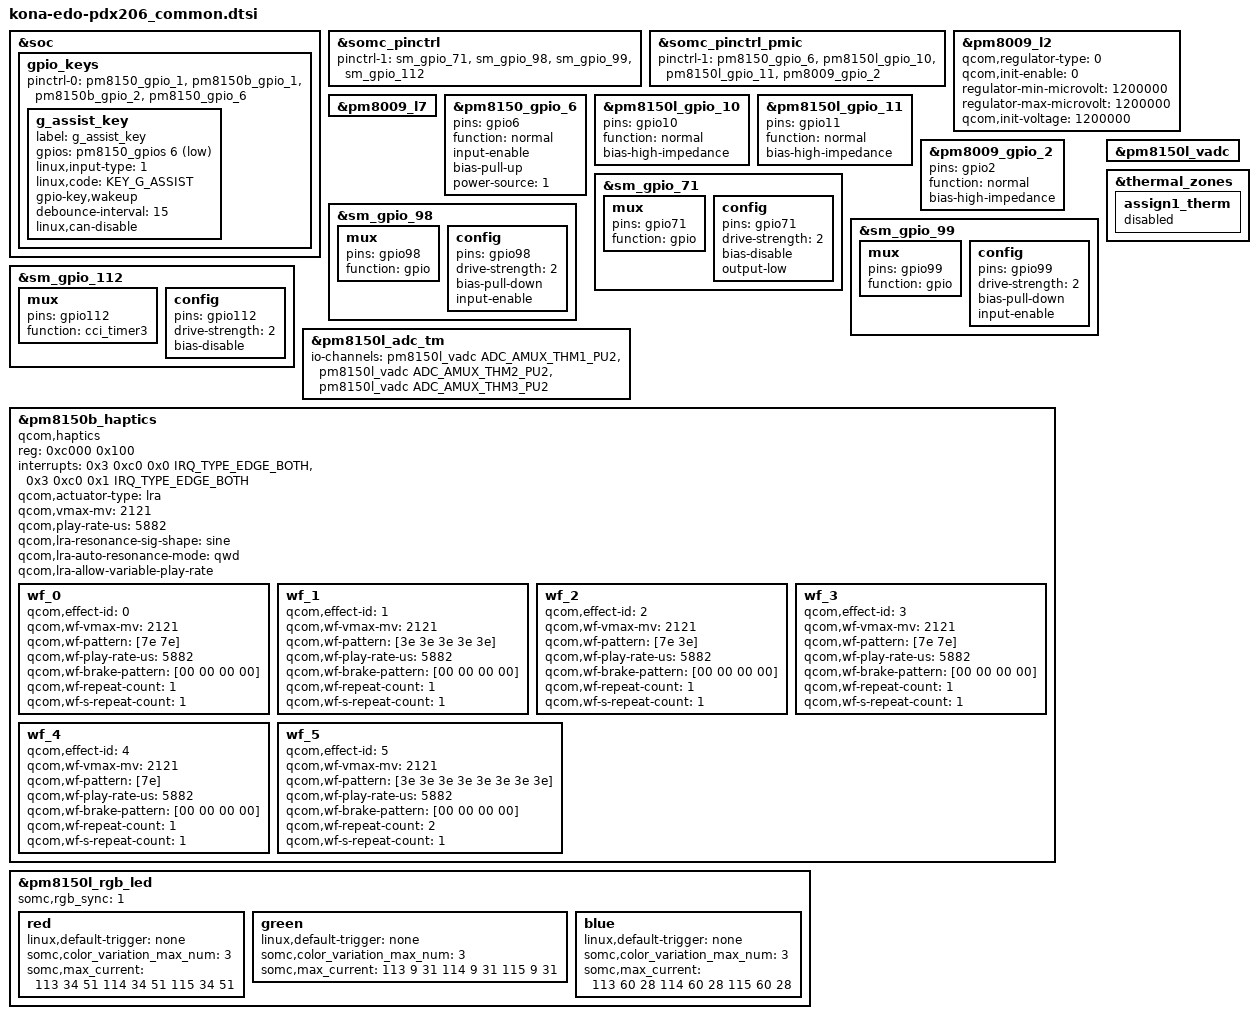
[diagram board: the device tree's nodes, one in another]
/* arch/arm64/boot/dts/vendor/somc/kona-edo-pdx206_common.dtsi
 *
 * This program is free software; you can redistribute it and/or modify
 * it under the terms of the GNU General Public License version 2 and
 * only version 2 as published by the Free Software Foundation.
 *
 * This program is distributed in the hope that it will be useful,
 * but WITHOUT ANY WARRANTY; without even the implied warranty of
 * MERCHANTABILITY or FITNESS FOR A PARTICULAR PURPOSE.  See the
 * GNU General Public License for more details.
 */

#include "kona-edo-common.dtsi"

&soc {
	gpio_keys {
		pinctrl-0 = <&pm8150_gpio_1
			     &pm8150b_gpio_1
			     &pm8150b_gpio_2
			     &pm8150_gpio_6>;
		g_assist_key {
			label = "g_assist_key";
			gpios = <&pm8150_gpios 6 GPIO_ACTIVE_LOW>;
			linux,input-type = <1>;
			linux,code = <KEY_G_ASSIST>;
			gpio-key,wakeup;
			debounce-interval = <15>;
			linux,can-disable;
		};
	};
};

&somc_pinctrl {
	/* If product common default setting is needed,
	fill pinctrl-1 value in <product>_common.dtsi */
	pinctrl-1 = <&sm_gpio_71 &sm_gpio_98 &sm_gpio_99 &sm_gpio_112>;
};

&somc_pinctrl_pmic {
	/* If product common PMIC default setting is needed,
	fill pinctrl-1 value in <product>_common.dtsi */
	pinctrl-1 = <&pm8150_gpio_6 &pm8150l_gpio_10 &pm8150l_gpio_11 &pm8009_gpio_2>;
};

/* Regulator config */
&pm8009_l2 {
	qcom,regulator-type = <0>;      /* LDO */
	qcom,init-enable = <0>;
	regulator-min-microvolt = <1200000>;
	regulator-max-microvolt = <1200000>;
	qcom,init-voltage = <1200000>;
	status = "okay";
};

&pm8009_l7 {
	status = "okay";
};

/* GPIO_6: G_ASSIST_N */
&pm8150_gpio_6 {
	pins = "gpio6";
	function = "normal";
	/delete-property/ bias-high-impedance;
	input-enable;
	bias-pull-up;
	power-source = <1>;
};

/* GPIO_10: NC */
&pm8150l_gpio_10 {
	pins = "gpio10";
	function = "normal";
	bias-high-impedance; /* DISABLE GPIO_10 */
};

/* GPIO_11: NC */
&pm8150l_gpio_11 {
	pins = "gpio11";
	function = "normal";
	/delete-property/ output-low;
	/delete-property/ drive-push-pull;
	/delete-property/ qcom,drive-strength;
	/delete-property/ power-source;
	bias-high-impedance; /* DISABLE GPIO_11 */
};

/* GPIO_2: NC */
&pm8009_gpio_2 {
	pins = "gpio2";
	function = "normal";
	/delete-property/ output-low;
	/delete-property/ drive-push-pull;
	/delete-property/ qcom,drive-strength;
	/delete-property/ power-source;
	bias-high-impedance; /* DISABLE GPIO_2 */
};

/* GPIO_71 : FRONTC_PWR_EN */
&sm_gpio_71 {
	mux {
		pins = "gpio71";
		function = "gpio";
	};

	config {
		pins = "gpio71";
		drive-strength = <2>;
		bias-disable;
		output-low;
	};
};

/* GPIO_98 : NC */
&sm_gpio_98 {
	mux {
		pins = "gpio98";
		function = "gpio";
	};

	config {
		pins = "gpio98";
		drive-strength = <2>;
		/delete-property/ bias-disable;
		bias-pull-down;
		input-enable;
	};
};

/* GPIO_99 : NC */
&sm_gpio_99 {
	mux {
		pins = "gpio99";
		function = "gpio";
	};

	config {
		pins = "gpio99";
		drive-strength = <2>;
		/delete-property/ bias-disable;
		bias-pull-down;
		/delete-property/ output-low;
		input-enable;
	};
};

/* GPIO_112 : XVS */
&sm_gpio_112 {
	mux {
		pins = "gpio112";
		function = "cci_timer3";
	};

	config {
		pins = "gpio112";
		drive-strength = <2>;
		/delete-property/ bias-pull-down;
		bias-disable;
		/delete-property/ input-enable;
	};
};

&pm8150l_vadc {
	/delete-node/ assign1_therm@55;
};

&pm8150l_adc_tm {
	io-channels = <&pm8150l_vadc ADC_AMUX_THM1_PU2>,
			<&pm8150l_vadc ADC_AMUX_THM2_PU2>,
			<&pm8150l_vadc ADC_AMUX_THM3_PU2>;

	/delete-node/ assign1_therm@55;
};

&thermal_zones {
	assign1_therm {
		status = "disable";
	};
};

&pm8150b_haptics {
	compatible = "qcom,haptics";
	reg = <0xc000 0x100>;
	interrupts = <0x3 0xc0 0x0 IRQ_TYPE_EDGE_BOTH>,
		     <0x3 0xc0 0x1 IRQ_TYPE_EDGE_BOTH>;
	interrupt-names = "hap-sc-irq", "hap-play-irq";
	qcom,actuator-type = "lra";
	qcom,vmax-mv = <2121>;
	qcom,play-rate-us = <5882>;
	qcom,lra-resonance-sig-shape = "sine";
	qcom,lra-auto-resonance-mode = "qwd";
	qcom,lra-allow-variable-play-rate;

	wf_0 {
		/* CLICK */
		qcom,effect-id = <0>;
		qcom,wf-vmax-mv = <2121>;
		qcom,wf-pattern = [7e 7e];
		qcom,wf-play-rate-us = <5882>;
		qcom,wf-brake-pattern = [00 00 00 00];
		qcom,wf-repeat-count = <1>;
		qcom,wf-s-repeat-count = <1>;
	};

	wf_1 {
		/* DOUBLE CLICK */
		qcom,effect-id = <1>;
		qcom,wf-vmax-mv = <2121>;
		qcom,wf-pattern = [3e 3e 3e 3e 3e];
		qcom,wf-play-rate-us = <5882>;
		qcom,wf-brake-pattern = [00 00 00 00];
		qcom,wf-repeat-count = <1>;
		qcom,wf-s-repeat-count = <1>;
	};

	wf_2 {
		/* TICK */
		qcom,effect-id = <2>;
		qcom,wf-vmax-mv = <2121>;
		qcom,wf-pattern = [7e 3e];
		qcom,wf-play-rate-us = <5882>;
		qcom,wf-brake-pattern = [00 00 00 00];
		qcom,wf-repeat-count = <1>;
		qcom,wf-s-repeat-count = <1>;
	};

	wf_3 {
		/* THUD */
		qcom,effect-id = <3>;
		qcom,wf-vmax-mv = <2121>;
		qcom,wf-pattern = [7e 7e];
		qcom,wf-play-rate-us = <5882>;
		qcom,wf-brake-pattern = [00 00 00 00];
		qcom,wf-repeat-count = <1>;
		qcom,wf-s-repeat-count = <1>;
	};

	wf_4 {
		/* POP */
		qcom,effect-id = <4>;
		qcom,wf-vmax-mv = <2121>;
		qcom,wf-pattern = [7e];
		qcom,wf-play-rate-us = <5882>;
		qcom,wf-brake-pattern = [00 00 00 00];
		qcom,wf-repeat-count = <1>;
		qcom,wf-s-repeat-count = <1>;
	};

	wf_5 {
		/* HEAVY CLICK */
		qcom,effect-id = <5>;
		qcom,wf-vmax-mv = <2121>;
		qcom,wf-pattern = [3e 3e 3e 3e 3e 3e 3e 3e];
		qcom,wf-play-rate-us = <5882>;
		qcom,wf-brake-pattern = [00 00 00 00];
		qcom,wf-repeat-count = <2>;
		qcom,wf-s-repeat-count = <1>;
	};

};

&pm8150l_rgb_led {
	somc,rgb_sync = <1>;
	red {
		linux,default-trigger = "none";
		somc,color_variation_max_num = <3>;
		somc,max_current = <
			113 34 51
			114 34 51
			115 34 51>;
	};
	green {
		linux,default-trigger = "none";
		somc,color_variation_max_num = <3>;
		somc,max_current = <
			113 9 31
			114 9 31
			115 9 31>;
	};
	blue {
		linux,default-trigger = "none";
		somc,color_variation_max_num = <3>;
		somc,max_current = <
			113 60 28
			114 60 28
			115 60 28>;
	};
};

#include "sec_touchscreen_pdx206.dtsi"
#include "usb-dp-edo-pdx206.dtsi"
#include "charger-edo-common.dtsi"
#include "charger-edo-pdx206.dtsi"
